# STM32U083 register map
File version: 1.0
CPU: CM0+ r0p1, little endian, MPU, no FPU, 4 interrupt priority bits
Registers are 32-bit, read-write, reset 0x0 unless marked. A register's access mark holds for its fields unless they carry their own. Offsets are from the block's base; [hi:lo] are bit positions.

## RCC — RCC address block description
Base 0x40021000
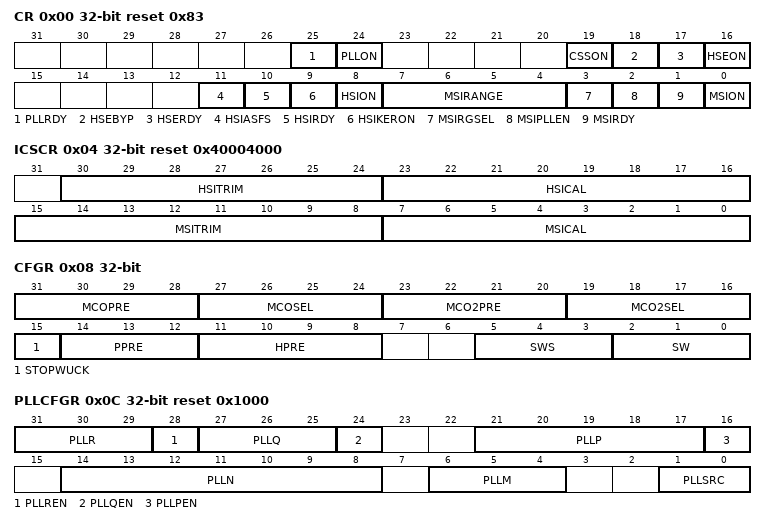
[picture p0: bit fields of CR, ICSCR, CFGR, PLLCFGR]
0x00 CR access per field reset 0x83 — Clock control register
  [25] PLLRDY ro — PLL clock ready flag Set by hardware to indicate that the PLL is locked.
  [24] PLLON rw — PLL enable Set and cleared by software to enable the PLL. Cleared by hardware when entering Stop, Standby or Shutdown mode. This bit cannot be reset if the PLL clock is used as the system clock.
  [19] CSSON rw — Clock security system enable Set by software to enable the clock security system. When CSSON is set, the clock detector is enabled by hardware when the HSE oscillator is ready, and disabled by hardware if a HSE clock failure is detected. This bit is set only and is cleared by reset.
  [18] HSEBYP rw — HSE crystal oscillator bypass Set and cleared by software to bypass the oscillator with an external clock. The external clock must be enabled with the HSEON bit set, to be used by the device. The HSEBYP bit can be written only if the HSE oscillator is disabled.
  [17] HSERDY ro — HSE clock ready flag Set by hardware to indicate that the HSE oscillator is stable. Note: Once the HSEON bit is cleared, HSERDY goes low after 6 HSE clock cycles.
  [16] HSEON rw — HSE clock enable Set and cleared by software. Cleared by hardware to stop the HSE oscillator when entering Stop, Standby, or Shutdown mode. This bit cannot be reset if the HSE oscillator is used directly or indirectly as the system clock.
  [11] HSIASFS ro — HSI16 automatic start from Stop Set and cleared by software. When the system wake-up clock is MSI, this bit is used to wake up the HSI16 is parallel of the system wake-up.
  [10] HSIRDY ro — HSI16 clock ready flag Set by hardware to indicate that HSI16 oscillator is stable. This bit is set only when HSI16 is enabled by software by setting HSION. Note: Once the HSION bit is cleared, HSIRDY goes low after 6 HSI16 clock cycles.
  [9] HSIKERON rw — HSI16 always enable for peripheral kernels. Set and cleared by software to force HSI16 ON even in Stop modes. The HSI16 can only feed USART1, USART2, CEC and I2C1 peripherals configured with HSI16 as kernel clock. Keeping the HSI16 ON in Stop mode allows avoiding to slow down the communication speed because of the HSI16 startup time. This bit has no effect on HSION value.
  [8] HSION rw — HSI16 clock enable Set and cleared by software. Cleared by hardware to stop the HSI16 oscillator when entering Stop, Standby, or Shutdown mode. Forced by hardware to keep the HSI16 oscillator ON when it is used directly or indirectly as system clock (also when leaving Stop, Standby, or Shutdown modes, or in case of failure of the HSE oscillator used for system clock).
  [7:4] MSIRANGE rw — MSI clock ranges These bits are configured by software to choose the frequency range of MSI when MSIRGSEL is set.12 frequency ranges are available: others: not allowed (hardware write protection) Note: Warning: MSIRANGE can be modified when MSI is OFF (MSION=0) or when MSI is ready (MSIRDY=1). MSIRANGE must NOT be modified when MSI is ON and NOT ready (MSION=1 and MSIRDY=0)
  [3] MSIRGSEL rw — MSI clock range selection Set by software to select the MSI clock range with MSIRANGE[3:0]. Write 0 has no effect. After a standby or a reset MSIRGSEL is at 0 and the MSI range value is provided by MSISRANGE in CSR register.
  [2] MSIPLLEN rw — MSI clock PLL enable Set and cleared by software to enable/ disable the PLL part of the MSI clock source. MSIPLLEN must be enabled after LSE is enabled (LSEON enabled) and ready (LSERDY set by hardware).There is a hardware protection to avoid enabling MSIPLLEN if LSE is not ready. This bit is cleared by hardware when LSE is disabled (LSEON = 0) or when the Clock Security System on LSE detects a LSE failure (refer to RCC_CSR register).
  [1] MSIRDY ro — MSI clock ready flag This bit is set by hardware to indicate that the MSI oscillator is stable. Note: Once the MSION bit is cleared, MSIRDY goes low after 6 MSI clock cycles.
  [0] MSION rw — MSI clock enable This bit is set and cleared by software. Cleared by hardware to stop the MSI oscillator when entering Stop, Standby or Shutdown mode. Set by hardware to force the MSI oscillator ON when exiting Standby or Shutdown mode. Set by hardware to force the MSI oscillator ON when STOPWUCK=0 when exiting from Stop modes, or in case of a failure of the HSE oscillator Set by hardware when used directly or indirectly as system clock.
0x04 ICSCR access per field reset 0x40004000 (reset mask 0xFF00FF00) — Internal clock sources calibration register
  [30:24] HSITRIM rw — HSI16 clock trimming These bits provide an additional user-programmable trimming value that is added to the HSICAL[7:0] bits. It can be programmed to adjust to variations in voltage and temperature that influence the frequency of the HSI16. The default value is 64 when added to the HSICAL value, trim the HSI16 to 161MHz 1 11%.
  [23:16] HSICAL ro — HSI16 clock calibration These bits are initialized at startup with the factory-programmed HSI16 calibration trim value. When HSITRIM is written, HSICAL is updated with the sum of HSITRIM and the factory trim value.
  [15:8] MSITRIM rw — MSI clock trimming These bits provide an additional user-programmable trimming value that is added to the MSICAL[7:0] bits. It can be programmed to adjust to variations in voltage and temperature that influence the frequency of the MSI.
  [7:0] MSICAL ro — MSI clock calibration These bits are initialized at startup with the factory-programmed MSI calibration trim value. When MSITRIM is written, MSICAL is updated with the sum of MSITRIM and the factory trim value.
0x08 CFGR access per field — Clock configuration register
  [31:28] MCOPRE rw — Microcontroller clock output prescaler This bitfield is controlled by software. It sets the division factor of the clock sent to the MCO output as follows: ... Others: reserved It is highly recommended to set this field before the MCO output is enabled.
  [27:24] MCOSEL rw — Microcontroller clock output clock selector This bitfield is controlled by software. It sets the clock selector for MCO output as follows: Others: Reserved Note: This clock output may have some truncated cycles at startup or during MCO clock source switching.
  [23:20] MCO2PRE rw — Microcontroller clock output 2 prescaler This bitfield is controlled by software. It sets the division factor of the clock sent to the MCO2 output as follows: ... Others: reserved It is highly recommended to set this field before the MCO2 output is enabled.
  [19:16] MCO2SEL rw — Microcontroller clock output 2 clock selector This bitfield is controlled by software. It sets the clock selector for MCO2 output as follows: Others: Reserved Note: This clock output may have some truncated cycles at startup or during MCO2 clock source switching.
  [15] STOPWUCK rw — Wake-up from Stop and CSS backup clock selection Set and cleared by software to select the system clock used when exiting Stop mode. The selected clock is also used as emergency clock for the Clock Security System on HSE. Warning: STOPWUCK must not be modified when the Clock Security System is enabled by HSECSSON in RCC_CR register and the system clock is HSE (SWS=10) or a switch on HSE is requested (SW=10).
  [14:12] PPRE rw — APB prescaler This bitfield is controlled by software. To produce PCLK clock, it sets the division factor of HCLK clock as follows: 0xx: 1
  [11:8] HPRE rw — AHB prescaler This bitfield is controlled by software. To produce HCLK clock, it sets the division factor of SYSCLK clock as follows: 0xxx: 1 Caution: Depending on the device voltage range, the software has to set correctly these bits to ensure that the system frequency does not exceed the maximum allowed frequency (for more details, refer to Section14.1.4: Dynamic voltage scaling management). After a write operation to these bits and before decreasing the voltage range, this register must be read to be sure that the new value has been taken into account.
  [5:3] SWS ro — System clock switch status This bitfield is controlled by hardware to indicate the clock source used as system clock: Others: Reserved
  [2:0] SW rw — System clock switch This bitfield is controlled by software and hardware. The bitfield selects the clock for SYSCLK as follows: Others: Reserved The setting is forced by hardware to 000 (HSISYS selected) when the MCU exits Stop, Standby, or Shutdown mode, or when the setting is 001 (HSE selected) and HSE oscillator failure is detected.
0x0C PLLCFGR reset 0x1000 — PLL configuration register
  [31:29] PLLR — PLL VCO division factor R for PLLRCLK clock output This bitfield is controlled by software. It sets the PLL VCO division factor R as follows: The bitfield can be written only when the PLL is disabled. The PLLRCLK clock can be selected as system clock. Caution: The software must set this bitfield so as not to exceed 122MHz on this clock.
  [28] PLLREN — PLLRCLK clock output enable This bit is controlled by software to enable/disable the PLLRCLK clock output of the PLL: This bit cannot be written when PLLRCLK output of the PLL is selected for system clock. Disabling the PLLRCLK clock output, when not used, allows saving power.
  [27:25] PLLQ — PLL VCO division factor Q for PLLQCLK clock output This bitfield is controlled by software. It sets the PLL VCO division factor Q as follows: The bitfield can be written only when the PLL is disabled. Caution: The software must set this bitfield so as not to exceed 541MHz on this clock.
  [24] PLLQEN — PLLQCLK clock output enable This bit is controlled by software to enable/disable the PLLQCLK clock output of the PLL: Disabling the PLLQCLK clock output, when not used, allows saving power.
  [21:17] PLLP — PLL VCO division factor P for PLLPCLK clock output This bitfield is controlled by software. It sets the PLL VCO division factor P as follows: ... The bitfield can be written only when the PLL is disabled. Caution: The software must set this bitfield so as not to exceed 541MHz on this clock.
  [16] PLLPEN — PLLPCLK clock output enable This bit is controlled by software to enable/disable the PLLPCLK clock output of the PLL: Disabling the PLLPCLK clock output, when not used, allows saving power.
  [14:8] PLLN — PLL frequency multiplication factor N This bit is controlled by software to set the division factor of the f<sub>VCO</sub> feedback divider (that determines the PLL multiplication ratio) as follows: ... ... The bitfield can be written only when the PLL is disabled. Caution: The software must set these bits so that the VCO output frequency is between 96 and 3441MHz.
  [6:4] PLLM — Division factor M of the PLL input clock divider This bit is controlled by software to divide the PLL input clock before the actual phase-locked loop, as follows: The bitfield can be written only when the PLL is disabled. Caution: The software must set these bits so that the PLL input frequency after the /M divider is between 2.66 and 161MHz.
  [1:0] PLLSRC — PLL input clock source This bit is controlled by software to select PLL clock source, as follows: The bitfield can be written only when the PLL is disabled. When the PLL is not used, selecting 00 allows saving power.
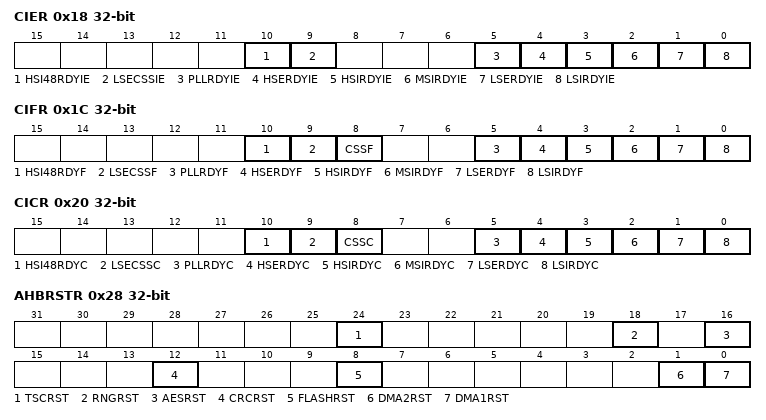
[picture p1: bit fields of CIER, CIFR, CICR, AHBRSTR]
0x18 CIER — Clock interrupt enable register
  [10] HSI48RDYIE — HSI48 ready interrupt enable Set and cleared by software to enable/disable interrupt caused by the internal HSI48 oscillator.
  [9] LSECSSIE — LSE clock security system interrupt enable Set and cleared by software to enable/disable interrupt caused by the clock security system on LSE.
  [5] PLLRDYIE — PLL ready interrupt enable Set and cleared by software to enable/disable interrupt caused by PLL lock:
  [4] HSERDYIE — HSE ready interrupt enable Set and cleared by software to enable/disable interrupt caused by the HSE oscillator stabilization:
  [3] HSIRDYIE — HSI16 ready interrupt enable Set and cleared by software to enable/disable interrupt caused by the HSI16 oscillator stabilization:
  [2] MSIRDYIE — MSI ready interrupt enable Set and cleared by software to enable/disable interrupt caused by the MSI oscillator stabilization.
  [1] LSERDYIE — LSE ready interrupt enable Set and cleared by software to enable/disable interrupt caused by the LSE oscillator stabilization:
  [0] LSIRDYIE — LSI ready interrupt enable Set and cleared by software to enable/disable interrupt caused by the LSI oscillator stabilization:
0x1C CIFR ro — Clock interrupt flag register
  [10] HSI48RDYF — HSI48 ready interrupt flag Set by hardware when the HSI48 clock becomes stable and HSI48RDYIE is set in a response to setting the HSI48ON (refer to RCC clock recovery RC register (RCC_CRRCR)). Cleared by software setting the HSI48RDYC bit.
  [9] LSECSSF — LSE clock security system interrupt flag Set by hardware when a failure is detected in the LSE oscillator. Cleared by software by setting the LSECSSC bit.
  [8] CSSF — HSE clock security system interrupt flag Set by hardware when a failure is detected in the HSE oscillator. Cleared by software setting the CSSC bit.
  [5] PLLRDYF — PLL ready interrupt flag Set by hardware when the PLL locks and PLLRDYIE is set. Cleared by software setting the PLLRDYC bit.
  [4] HSERDYF — HSE ready interrupt flag Set by hardware when the HSE clock becomes stable and HSERDYIE is set. Cleared by software setting the HSERDYC bit.
  [3] HSIRDYF — HSI16 ready interrupt flag Set by hardware when the HSI16 clock becomes stable and HSIRDYIE is set in a response to setting the HSION (refer to Clock control register (RCC_CR)). When HSION is not set but the HSI16 oscillator is enabled by the peripheral through a clock request, this bit is not set and no interrupt is generated. Cleared by software setting the HSIRDYC bit.
  [2] MSIRDYF — MSI ready interrupt flag Set by hardware when the MSI clock becomes stable and MSIRDYDIE is set. Cleared by software setting the MSIRDYC bit.
  [1] LSERDYF — LSE ready interrupt flag Set by hardware when the LSE clock becomes stable and LSERDYDIE is set. Cleared by software setting the LSERDYC bit.
  [0] LSIRDYF — LSI ready interrupt flag Set by hardware when the LSI clock becomes stable and LSIRDYDIE is set. Cleared by software setting the LSIRDYC bit.
0x20 CICR wo — Clock interrupt clear register
  [10] HSI48RDYC — HSI48 oscillator ready interrupt clear This bit is set by software to clear the HSI48RDYF flag.
  [9] LSECSSC — LSE Clock security system interrupt clear This bit is set by software to clear the LSECSSF flag.
  [8] CSSC — Clock security system interrupt clear This bit is set by software to clear the HSECSSF flag.
  [5] PLLRDYC — PLL ready interrupt clear This bit is set by software to clear the PLLRDYF flag.
  [4] HSERDYC — HSE ready interrupt clear This bit is set by software to clear the HSERDYF flag.
  [3] HSIRDYC — HSI16 ready interrupt clear This bit is set software to clear the HSIRDYF flag.
  [2] MSIRDYC — MSI ready interrupt clear This bit is set by software to clear the MSIRDYF flag.
  [1] LSERDYC — LSE ready interrupt clear This bit is set by software to clear the LSERDYF flag.
  [0] LSIRDYC — LSI ready interrupt clear This bit is set by software to clear the LSIRDYF flag.
0x28 AHBRSTR — AHB peripheral reset register
  [24] TSCRST — Touch sensing controller reset Set and cleared by software.
  [18] RNGRST — Random number generator reset Set and cleared by software.
  [16] AESRST — AES hardware accelerator reset Set and cleared by software.
  [12] CRCRST — CRC reset Set and cleared by software.
  [8] FLASHRST — Flash memory interface reset Set and cleared by software. This bit can only be set when the flash memory is in power down mode.
  [1] DMA2RST — DMA2 and DMAMUX reset Set and cleared by software.
  [0] DMA1RST — DMA1 and DMAMUX reset Set and cleared by software.
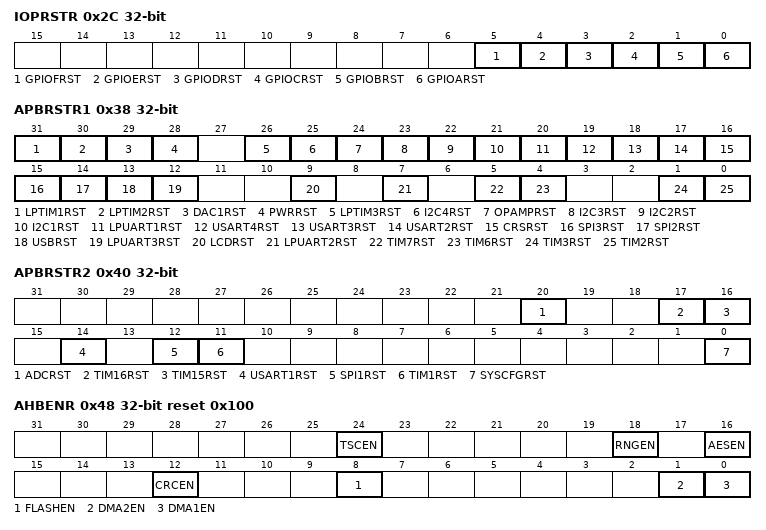
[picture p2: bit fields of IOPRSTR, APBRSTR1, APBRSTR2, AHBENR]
0x2C IOPRSTR — I/O port reset register
  [5] GPIOFRST — I/O port F reset This bit is set and cleared by software.
  [4] GPIOERST — I/O port E reset This bit is set and cleared by software.
  [3] GPIODRST — I/O port D reset This bit is set and cleared by software.
  [2] GPIOCRST — I/O port C reset This bit is set and cleared by software.
  [1] GPIOBRST — I/O port B reset This bit is set and cleared by software.
  [0] GPIOARST — I/O port A reset This bit is set and cleared by software.
0x38 APBRSTR1 — APB peripheral reset register 1
  [31] LPTIM1RST — Low Power Timer 1 reset Set and cleared by software.
  [30] LPTIM2RST — Low Power Timer 2 reset Set and cleared by software.
  [29] DAC1RST — DAC1 interface reset Set and cleared by software.
  [28] PWRRST — Power interface reset Set and cleared by software.
  [26] LPTIM3RST — LPTIM3 reset Set and cleared by software.
  [25] I2C4RST — I2C4 reset<sup>(1)</sup> Set and cleared by software.
  [24] OPAMPRST — OPAMP reset Set and cleared by software.
  [23] I2C3RST — I2C3 reset Set and cleared by software.
  [22] I2C2RST — I2C2 reset Set and cleared by software.
  [21] I2C1RST — I2C1 reset Set and cleared by software.
  [20] LPUART1RST — LPUART1 reset Set and cleared by software.
  [19] USART4RST — USART4 reset Set and cleared by software.
  [18] USART3RST — USART3 reset Set and cleared by software.
  [17] USART2RST — USART2 reset Set and cleared by software.
  [16] CRSRST — CRS reset<sup>(1)</sup> Set and cleared by software.
  [15] SPI3RST — SPI3 reset<sup>(1)</sup> Set and cleared by software.
  [14] SPI2RST — SPI2 reset Set and cleared by software.
  [13] USBRST — USB reset<sup>(1)</sup> Set and cleared by software.
  [12] LPUART3RST — LPUART3 reset<sup>(1)</sup> Set and cleared by software.
  [9] LCDRST — LCD reset<sup>(1)</sup> Set and cleared by software.
  [7] LPUART2RST — LPUART2 reset Set and cleared by software.
  [5] TIM7RST — TIM7 timer reset Set and cleared by software.
  [4] TIM6RST — TIM6 timer reset Set and cleared by software.
  [1] TIM3RST — TIM3 timer reset Set and cleared by software.
  [0] TIM2RST — TIM2 timer reset Set and cleared by software.
0x40 APBRSTR2 — APB peripheral reset register 2
  [20] ADCRST — ADC reset Set and cleared by software.
  [17] TIM16RST — TIM16 timer reset Set and cleared by software.
  [16] TIM15RST — TIM15 timer reset Set and cleared by software.
  [14] USART1RST — USART1 reset Set and cleared by software.
  [12] SPI1RST — SPI1 reset Set and cleared by software.
  [11] TIM1RST — TIM1 timer reset Set and cleared by software.
  [0] SYSCFGRST — SYSCFG, COMP and VREFBUF reset Set and cleared by software.
0x48 AHBENR reset 0x100 — AHB peripheral clock enable register
  [24] TSCEN — Touch sensing controller clock enable Set and cleared by software.
  [18] RNGEN — Random number generator clock enable Set and cleared by software.
  [16] AESEN — AES hardware accelerator Set and cleared by software.
  [12] CRCEN — CRC clock enable Set and cleared by software.
  [8] FLASHEN — Flash memory interface clock enable Set and cleared by software. This bit can only be cleared when the flash memory is in power down mode.
  [1] DMA2EN — DMA2 and DMAMUX clock enable Set and cleared by software. DMAMUX is enabled as long as at least one DMA peripheral is enabled.
  [0] DMA1EN — DMA1 and DMAMUX clock enable Set and cleared by software. DMAMUX is enabled as long as at least one DMA peripheral is enabled.
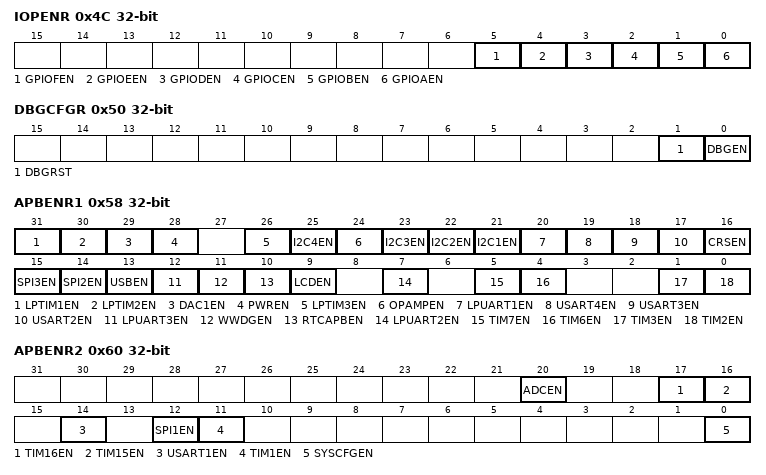
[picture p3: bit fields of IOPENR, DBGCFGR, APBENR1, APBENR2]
0x4C IOPENR — I/O port clock enable register
  [5] GPIOFEN — I/O port F clock enable This bit is set and cleared by software.
  [4] GPIOEEN — I/O port E clock enable<sup>(1)</sup> This bit is set and cleared by software.
  [3] GPIODEN — I/O port D clock enable This bit is set and cleared by software.
  [2] GPIOCEN — I/O port C clock enable This bit is set and cleared by software.
  [1] GPIOBEN — I/O port B clock enable This bit is set and cleared by software.
  [0] GPIOAEN — I/O port A clock enable This bit is set and cleared by software.
0x50 DBGCFGR — Debug configuration register
  [1] DBGRST — Debug support reset Set and cleared by software.
  [0] DBGEN — Debug support clock enable Set and cleared by software.
0x58 APBENR1 — APB peripheral clock enable register 1
  [31] LPTIM1EN — LPTIM1 clock enable Set and cleared by software.
  [30] LPTIM2EN — LPTIM2 clock enable Set and cleared by software.
  [29] DAC1EN — DAC1 interface clock enable Set and cleared by software.
  [28] PWREN — Power interface clock enable Set and cleared by software.
  [26] LPTIM3EN — LPTIM3 clock enable Set and cleared by software.
  [25] I2C4EN — I2C4EN clock enable<sup>(1)</sup> Set and cleared by software.
  [24] OPAMPEN — OPAMP clock enable Set and cleared by software.
  [23] I2C3EN — I2C3 clock enable Set and cleared by software.
  [22] I2C2EN — I2C2 clock enable Set and cleared by software.
  [21] I2C1EN — I2C1 clock enable Set and cleared by software.
  [20] LPUART1EN — LPUART1 clock enable Set and cleared by software.
  [19] USART4EN — USART4 clock enable Set and cleared by software.
  [18] USART3EN — USART3 clock enable Set and cleared by software.
  [17] USART2EN — USART2 clock enable Set and cleared by software.
  [16] CRSEN — CRS clock enable<sup>(1)</sup> Set and cleared by software.
  [15] SPI3EN — SPI3 clock enable<sup>(1)</sup> Set and cleared by software.
  [14] SPI2EN — SPI2 clock enable Set and cleared by software.
  [13] USBEN — USB clock enable<sup>(1)</sup> Set and cleared by software.
  [12] LPUART3EN — LPUART3 clock enable Set and cleared by software.
  [11] WWDGEN — WWDG clock enable Set by software to enable the window watchdog clock. Cleared by hardware system reset This bit can also be set by hardware if the WWDG_SW option bit is 0.
  [10] RTCAPBEN — RTC APB clock enable Set and cleared by software.
  [9] LCDEN — LCD clock enable<sup>(1)</sup> Set and cleared by software.
  [7] LPUART2EN — LPUART2 clock enable Set and cleared by software.
  [5] TIM7EN — TIM7 timer clock enable Set and cleared by software.
  [4] TIM6EN — TIM6 timer clock enable Set and cleared by software.
  [1] TIM3EN — TIM3 timer clock enable Set and cleared by software.
  [0] TIM2EN — TIM2 timer clock enable Set and cleared by software.
0x60 APBENR2 — APB peripheral clock enable register 2
  [20] ADCEN — ADC clock enable Set and cleared by software.
  [17] TIM16EN — TIM16 timer clock enable Set and cleared by software.
  [16] TIM15EN — TIM15 timer clock enable Set and cleared by software.
  [14] USART1EN — USART1 clock enable Set and cleared by software.
  [12] SPI1EN — SPI1 clock enable Set and cleared by software.
  [11] TIM1EN — TIM1 timer clock enable Set and cleared by software.
  [0] SYSCFGEN — SYSCFG, COMP and VREFBUF clock enable Set and cleared by software.
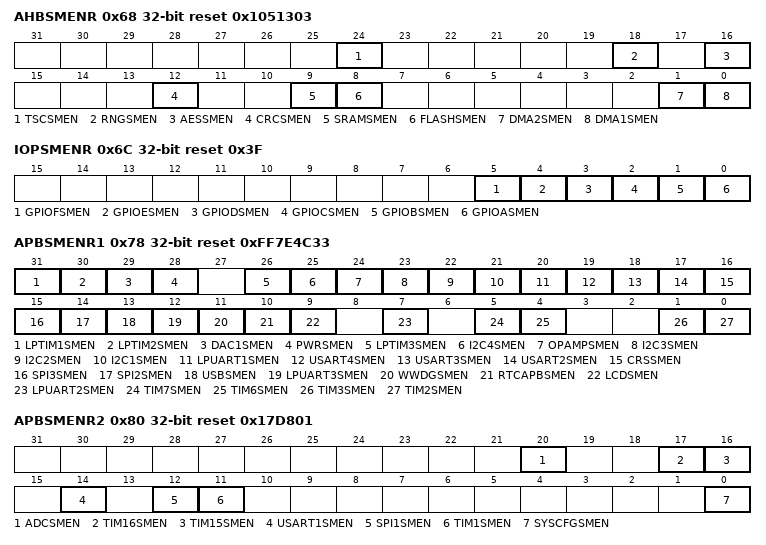
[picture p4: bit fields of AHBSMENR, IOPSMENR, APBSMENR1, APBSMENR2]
0x68 AHBSMENR reset 0x1051303 — AHB peripheral clock enable in Sleep/Stop mode register
  [24] TSCSMEN — TSC clock enable during Sleep and Stop mode Set and cleared by software.
  [18] RNGSMEN — RNG clock enable during Sleep and Stop mode Set and cleared by software.
  [16] AESSMEN — AES hardware accelerator clock enable during Sleep mode Set and cleared by software.
  [12] CRCSMEN — CRC clock enable during Sleep mode Set and cleared by software.
  [9] SRAMSMEN — SRAM clock enable during Sleep mode Set and cleared by software.
  [8] FLASHSMEN — Flash memory interface clock enable during Sleep mode Set and cleared by software. This bit can be activated only when the flash memory is in power down mode.
  [1] DMA2SMEN — DMA2 and DMAMUX clock enable during Sleep mode Set and cleared by software. Clock to DMAMUX during Sleep mode is enabled as long as the clock in Sleep mode is enabled to at least one DMA peripheral.
  [0] DMA1SMEN — DMA1 and DMAMUX clock enable during Sleep mode Set and cleared by software. Clock to DMAMUX during Sleep mode is enabled as long as the clock in Sleep mode is enabled to at least one DMA peripheral.
0x6C IOPSMENR reset 0x3F — I/O port in Sleep mode clock enable register
  [5] GPIOFSMEN — I/O port F clock enable during Sleep mode Set and cleared by software.
  [4] GPIOESMEN — I/O port E clock enable during Sleep mode Set and cleared by software.
  [3] GPIODSMEN — I/O port D clock enable during Sleep mode<sup>(1)</sup> Set and cleared by software.
  [2] GPIOCSMEN — I/O port C clock enable during Sleep mode Set and cleared by software.
  [1] GPIOBSMEN — I/O port B clock enable during Sleep mode Set and cleared by software.
  [0] GPIOASMEN — I/O port A clock enable during Sleep mode Set and cleared by software.
0x78 APBSMENR1 reset 0xFF7E4C33 — APB peripheral clock enable in Sleep/Stop mode register 1
  [31] LPTIM1SMEN — Low Power Timer 1 clock enable during Sleep and Stop modes Set and cleared by software.
  [30] LPTIM2SMEN — Low Power Timer 2 clock enable during Sleep and Stop modes Set and cleared by software.
  [29] DAC1SMEN — DAC1 interface clock enable during Sleep and Stop modes Set and cleared by software.
  [28] PWRSMEN — Power interface clock enable during Sleep mode Set and cleared by software.
  [26] LPTIM3SMEN — Low power timer 3 clock enable during Sleep mode Set and cleared by software.
  [25] I2C4SMEN — I2C4 clock enable during Sleep mode<sup>(1)</sup> Set and cleared by software.
  [24] OPAMPSMEN — OPAMP clock enable during Sleep and Stop modes Set and cleared by software.
  [23] I2C3SMEN — I2C3 clock enable during Sleep mode Set and cleared by software.
  [22] I2C2SMEN — I2C2 clock enable during Sleep mode Set and cleared by software.
  [21] I2C1SMEN — I2C1 clock enable during Sleep and Stop modes Set and cleared by software.
  [20] LPUART1SMEN — LPUART1 clock enable during Sleep and Stop modes Set and cleared by software.
  [19] USART4SMEN — USART4 clock enable during Sleep mode Set and cleared by software.
  [18] USART3SMEN — USART3 clock enable during Sleep mode Set and cleared by software.
  [17] USART2SMEN — USART2 clock enable during Sleep and Stop modes Set and cleared by software.
  [16] CRSSMEN — CRS clock enable during Sleep and Stop modes<sup>(1)</sup> Set and cleared by software.
  [15] SPI3SMEN — SPI3 clock enable during Sleep mode<sup>(1)</sup> Set and cleared by software.
  [14] SPI2SMEN — SPI2 clock enable during Sleep mode Set and cleared by software.
  [13] USBSMEN — USB clock enable during Sleep mode<sup>(1)</sup> Set and cleared by software.
  [12] LPUART3SMEN — LPUART3 clock enable during Sleep and Stop modes Set and cleared by software.
  [11] WWDGSMEN — WWDG clock enable during Sleep and Stop modes Set and cleared by software.
  [10] RTCAPBSMEN — RTC APB clock enable during Sleep mode Set and cleared by software.
  [9] LCDSMEN — LCD clock enable during Sleep mode<sup>(1)</sup> Set and cleared by software.
  [7] LPUART2SMEN — LPUART2 clock enable during Sleep and Stop modes Set and cleared by software.
  [5] TIM7SMEN — TIM7 timer clock enable during Sleep mode Set and cleared by software.
  [4] TIM6SMEN — TIM6 timer clock enable during Sleep mode Set and cleared by software.
  [1] TIM3SMEN — TIM3 timer clock enable during Sleep mode Set and cleared by software.
  [0] TIM2SMEN — TIM2 timer clock enable during Sleep mode Set and cleared by software.
0x80 APBSMENR2 reset 0x17D801 — APB peripheral clock enable in Sleep/Stop mode register 2
  [20] ADCSMEN — ADC clock enable during Sleep mode Set and cleared by software.
  [17] TIM16SMEN — TIM16 timer clock enable during Sleep mode Set and cleared by software.
  [16] TIM15SMEN — TIM15 timer clock enable during Sleep mode Set and cleared by software.
  [14] USART1SMEN — USART1 clock enable during Sleep and Stop modes Set and cleared by software.
  [12] SPI1SMEN — SPI1 clock enable during Sleep mode Set and cleared by software.
  [11] TIM1SMEN — TIM1 timer clock enable during Sleep mode Set and cleared by software.
  [0] SYSCFGSMEN — SYSCFG, COMP and VREFBUF clock enable during Sleep and Stop modes Set and cleared by software.
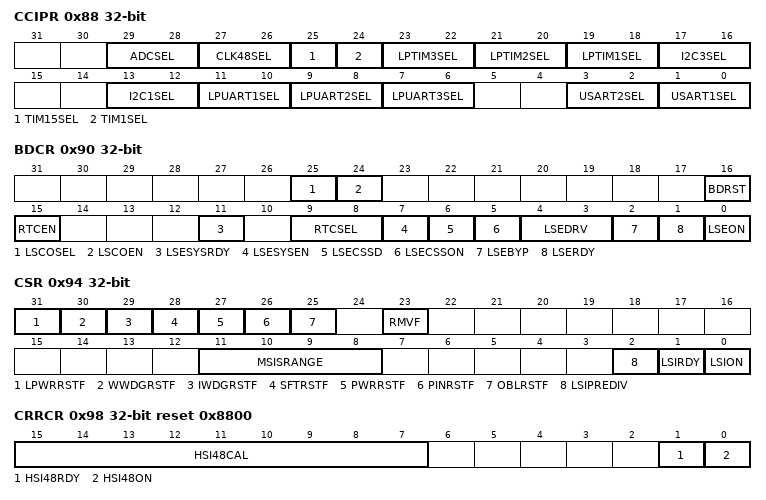
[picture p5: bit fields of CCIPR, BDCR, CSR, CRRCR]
0x88 CCIPR — Peripherals independent clock configuration register
  [29:28] ADCSEL — ADCs clock source selection This bitfield is controlled by software to select the clock source for ADC:
  [27:26] CLK48SEL — 481MHz clock source selection This bitfield is controlled by software to select the 481MHz clock source used by the USB FS and the RNG:
  [25] TIM15SEL — TIM15 clock source selection This bit is set and cleared by software. It selects TIM15 clock source as follows:
  [24] TIM1SEL — TIM1 clock source selection This bit is set and cleared by software. It selects TIM1 clock source as follows:
  [23:22] LPTIM3SEL — LPTIM3 clock source selection This bitfield is controlled by software to select LPTIM3 clock source as follows:
  [21:20] LPTIM2SEL — LPTIM2 clock source selection This bitfield is controlled by software to select LPTIM2 clock source as follows:
  [19:18] LPTIM1SEL — LPTIM1 clock source selection This bitfield is controlled by software to select LPTIM1 clock source as follows:
  [17:16] I2C3SEL — I2C3 clock source selection This bitfield is controlled by software to select I2C3 clock source as follows:
  [13:12] I2C1SEL — I2C1 clock source selection This bitfield is controlled by software to select I2C1 clock source as follows:
  [11:10] LPUART1SEL — LPUART1 clock source selection This bitfield is controlled by software to select LPUART1 clock source as follows:
  [9:8] LPUART2SEL — LPUART2 clock source selection This bitfield is controlled by software to select LPUART2 clock source as follows:
  [7:6] LPUART3SEL — LPUART3 clock source selection<sup>(1)</sup> This bitfield is controlled by software to select LPUART3 clock source as follows:
  [3:2] USART2SEL — USART2 clock source selection This bitfield is controlled by software to select USART2 clock source as follows:
  [1:0] USART1SEL — USART1 clock source selection This bitfield is controlled by software to select USART1 clock source as follows:
0x90 BDCR access per field — RTC domain control register
  [25] LSCOSEL rw — Low-speed clock output selection Set and cleared by software to select the low-speed output clock:
  [24] LSCOEN rw — Low-speed clock output (LSCO) enable Set and cleared by software.
  [16] BDRST rw — RTC domain software reset Set and cleared by software to reset the RTC domain:
  [15] RTCEN rw — RTC clock enable Set and cleared by software. The bit enables clock to RTC and TAMP.
  [11] LSESYSRDY ro — LSE clock ready for system usage This flag is set by hardware to indicate that the LSE clock is ready for being used by the system (see LSESYSEN bit). This flag is set when LSE clock is ready (LSEON1=11 and LSERDY1=11) and two LSE clock cycles after that LSESYSEN is set. Cleared by hardware to indicate that the LSE clock is not ready to be used by the system.
  [9:8] RTCSEL rw — RTC clock source selection Set by software to select the clock source for the RTC as follows: Once the RTC clock source is selected, it cannot be changed anymore unless the RTC domain is reset, or unless a failure is detected on LSE (LSECSSD is set). The BDRST bit can be used to reset this bitfield to 00.
  [7] LSESYSEN rw — LSE clock enable for system usage This bit must be set by software to enable the LSE clock for a system usage.
  [6] LSECSSD ro — CSS on LSE failure Detection Set by hardware to indicate when a failure is detected by the clock security system on the external 321kHz oscillator (LSE):
  [5] LSECSSON rw — CSS on LSE enable Set by software to enable the clock security system on LSE (321kHz) oscillator as follows: LSECSSON must be enabled after the LSE oscillator is enabled (LSEON bit enabled) and ready (LSERDY flag set by hardware), and after the RTCSEL bit is selected. Once enabled, this bit cannot be disabled, except after a LSE failure detection (LSECSSD =1). In that case the software must disable the LSECSSON bit.
  [4:3] LSEDRV rw — LSE oscillator drive capability Set by software to select the LSE oscillator drive capability as follows: Applicable when the LSE oscillator is in Xtal mode, as opposed to bypass mode.
  [2] LSEBYP rw — LSE oscillator bypass Set and cleared by software to bypass the LSE oscillator (in debug mode). This bit can be written only when the external 321kHz oscillator is disabled (LSEON=0 and LSERDY=0).
  [1] LSERDY ro — LSE oscillator ready Set and cleared by hardware to indicate when the external 321kHz oscillator is ready (stable): After the LSEON bit is cleared, LSERDY goes low after 6 external low-speed oscillator clock cycles.
  [0] LSEON rw — LSE oscillator enable Set and cleared by software to enable LSE oscillator:
0x94 CSR access per field (reset mask 0xFFFFFF) — Control/status register
  [31] LPWRRSTF ro — Low-power reset flag Set by hardware when a reset occurs due to illegal Stop, Standby, or Shutdown mode entry. Cleared by setting the RMVF bit. This operates only if nRST_STOP, nRST_STDBY or nRST_SHDW option bits are cleared.
  [30] WWDGRSTF ro — Window watchdog reset flag Set by hardware when a window watchdog reset occurs. Cleared by setting the RMVF bit.
  [29] IWDGRSTF ro — Independent window watchdog reset flag Set by hardware when an independent watchdog reset domain occurs. Cleared by setting the RMVF bit.
  [28] SFTRSTF ro — Software reset flag Set by hardware when a software reset occurs. Cleared by setting the RMVF bit.
  [27] PWRRSTF ro — BOR or POR/PDR flag Set by hardware when a BOR or POR/PDR occurs. Cleared by setting the RMVF bit.
  [26] PINRSTF ro — Pin reset flag Set by hardware when a reset from the NRST pin occurs. Cleared by setting the RMVF bit.
  [25] OBLRSTF ro — Option byte loader reset flag Set by hardware when a reset from the Option byte loading occurs. Cleared by setting the RMVF bit.
  [23] RMVF rw — Remove reset flags Set by software to clear the reset flags.
  [11:8] MSISRANGE rw — MSI range after Standby mode Set by software to chose the MSI frequency at startup. This range is used after exiting Standby mode until MSIRGSEL is set. After a pad or a power-on reset, the range is always 41MHz. MSISRANGE[3:0] can be written only when MSIRGSEL1=11. Others: Reserved Note: Changing the MSISRANGE[3:0] does not change the current MSI frequency.
  [2] LSIPREDIV rw — Internal low-speed oscillator pre-divided by 128 Set and reset by hardware to indicate when the low-speed internal RC oscillator has to be divided by 128. The software has to switch off the LSI before changing this bit.
  [1] LSIRDY ro — LSI oscillator ready Set and cleared by hardware to indicate when the LSI oscillator is ready (stable): After the LSION bit is cleared, LSIRDY goes low after 3 LSI oscillator clock cycles. This bit can be set even if LSION = 0 if the LSI is requested by the Clock Security System on LSE, by the Independent Watchdog or by the RTC.
  [0] LSION rw — LSI oscillator enable Set and cleared by software to enable/disable the LSI oscillator:
0x98 CRRCR access per field reset 0x8800 — RCC clock recovery RC register
  [15:7] HSI48CAL ro — HSI48 clock calibration These bits are initialized at startup with the factory-programmed HSI48 calibration trim value.
  [1] HSI48RDY ro — HSI48 clock ready flag<sup>(1)</sup> The flag is set when the HSI48 clock is ready for use.
  [0] HSI48ON rw — HSI48 RC oscillator enable<sup>(1)</sup>
